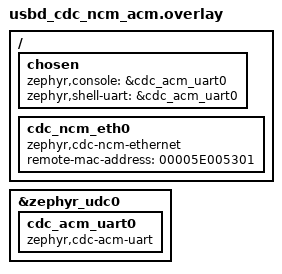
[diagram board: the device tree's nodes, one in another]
/*
 * CDC-NCM networking + CDC-ACM console
 */

/ {
	chosen {
		zephyr,console = &cdc_acm_uart0;
		zephyr,shell-uart = &cdc_acm_uart0;
	};

	cdc_ncm_eth0: cdc_ncm_eth0 {
		compatible = "zephyr,cdc-ncm-ethernet";
		remote-mac-address = "00005E005301";
	};
};

&zephyr_udc0 {
	cdc_acm_uart0: cdc_acm_uart0 {
		compatible = "zephyr,cdc-acm-uart";
	};
};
